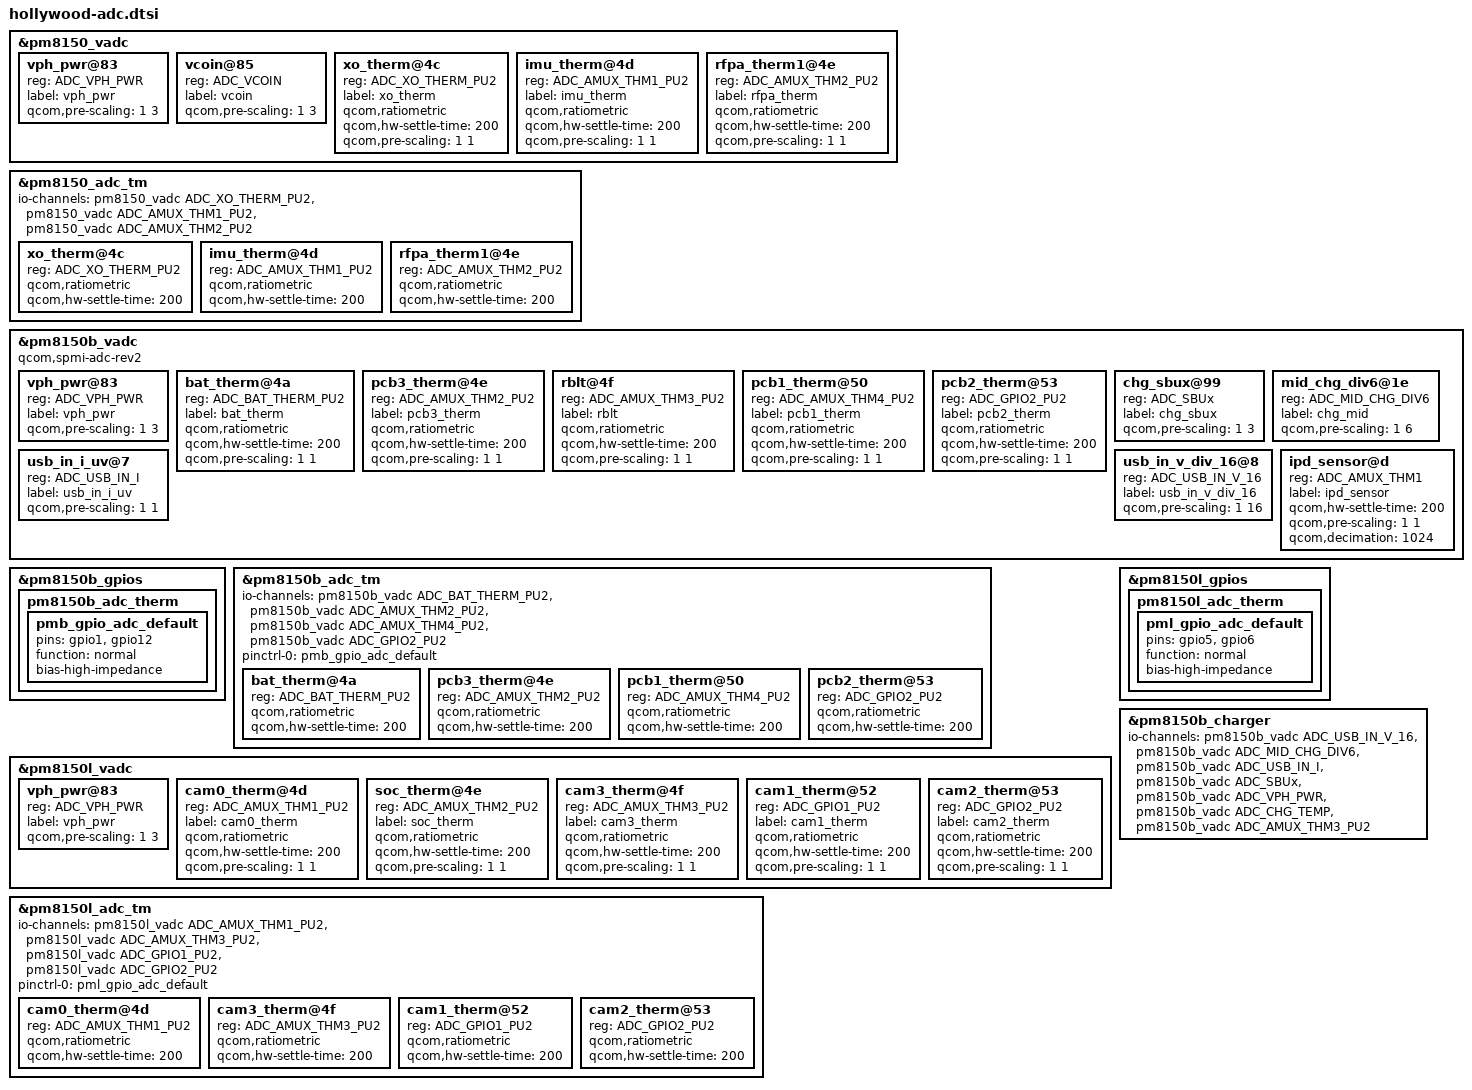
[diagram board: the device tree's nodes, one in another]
&pm8150_vadc {
	#address-cells = <1>;
	#size-cells = <0>;

	vph_pwr@83 {
		reg = <ADC_VPH_PWR>;
		label = "vph_pwr";
		qcom,pre-scaling = <1 3>;
	};

	vcoin@85 {
		reg = <ADC_VCOIN>;
		label = "vcoin";
		qcom,pre-scaling = <1 3>;
	};

	xo_therm@4c {
		reg = <ADC_XO_THERM_PU2>;
		label = "xo_therm";
		qcom,ratiometric;
		qcom,hw-settle-time = <200>;
		qcom,pre-scaling = <1 1>;
	};

	imu_therm@4d {
		reg = <ADC_AMUX_THM1_PU2>;
		label = "imu_therm";
		qcom,ratiometric;
		qcom,hw-settle-time = <200>;
		qcom,pre-scaling = <1 1>;
	};

	rfpa_therm1@4e {
		reg = <ADC_AMUX_THM2_PU2>;
		label = "rfpa_therm";
		qcom,ratiometric;
		qcom,hw-settle-time = <200>;
		qcom,pre-scaling = <1 1>;
	};
};

&pm8150_adc_tm {
	#address-cells = <1>;
	#size-cells = <0>;

	io-channels = <&pm8150_vadc ADC_XO_THERM_PU2>,
			<&pm8150_vadc ADC_AMUX_THM1_PU2>,
			<&pm8150_vadc ADC_AMUX_THM2_PU2>;

	xo_therm@4c {
		reg = <ADC_XO_THERM_PU2>;
		qcom,ratiometric;
		qcom,hw-settle-time = <200>;
	};

	imu_therm@4d {
		reg = <ADC_AMUX_THM1_PU2>;
		qcom,ratiometric;
		qcom,hw-settle-time = <200>;
	};

	rfpa_therm1@4e {
		reg = <ADC_AMUX_THM2_PU2>;
		qcom,ratiometric;
		qcom,hw-settle-time = <200>;
	};
};

&pm8150b_vadc {
	#address-cells = <1>;
	#size-cells = <0>;
	compatible = "qcom,spmi-adc-rev2";
	vph_pwr@83 {
		reg = <ADC_VPH_PWR>;
		label = "vph_pwr";
		qcom,pre-scaling = <1 3>;
	};

	bat_therm@4a {
		reg = <ADC_BAT_THERM_PU2>;
		label = "bat_therm";
		qcom,ratiometric;
		qcom,hw-settle-time = <200>;
		qcom,pre-scaling = <1 1>;
	};

	pcb3_therm@4e {
		reg = <ADC_AMUX_THM2_PU2>;
		label = "pcb3_therm";
		qcom,ratiometric;
		qcom,hw-settle-time = <200>;
		qcom,pre-scaling = <1 1>;
	};

	rblt@4f {
		reg = <ADC_AMUX_THM3_PU2>;
		label = "rblt";
		qcom,ratiometric;
		qcom,hw-settle-time = <200>;
		qcom,pre-scaling = <1 1>;
	};

	pcb1_therm@50 {
		reg = <ADC_AMUX_THM4_PU2>;
		label = "pcb1_therm";
		qcom,ratiometric;
		qcom,hw-settle-time = <200>;
		qcom,pre-scaling = <1 1>;
	};

	pcb2_therm@53 {
		reg = <ADC_GPIO2_PU2>;
		label = "pcb2_therm";
		qcom,ratiometric;
		qcom,hw-settle-time = <200>;
		qcom,pre-scaling = <1 1>;
	};

	chg_sbux@99 {
		reg = <ADC_SBUx>;
		label = "chg_sbux";
		qcom,pre-scaling = <1 3>;
	};

	mid_chg_div6@1e {
		reg = <ADC_MID_CHG_DIV6>;
		label = "chg_mid";
		qcom,pre-scaling = <1 6>;
	};

	usb_in_i_uv@7 {
		reg = <ADC_USB_IN_I>;
		label = "usb_in_i_uv";
		qcom,pre-scaling = <1 1>;
	};

	usb_in_v_div_16@8 {
		reg = <ADC_USB_IN_V_16>;
		label = "usb_in_v_div_16";
		qcom,pre-scaling = <1 16>;
	};

	ipd_sensor@d{
		reg = <ADC_AMUX_THM1>;
		label = "ipd_sensor";
		qcom,hw-settle-time = <200>;
		qcom,pre-scaling = <1 1>;
		qcom,decimation = <1024>;
	};
};

&pm8150b_gpios {
	pm8150b_adc_therm {
		pmb_gpio_adc_default: pmb_gpio_adc_default {
			pins = "gpio1", "gpio12";
			function = "normal";
			bias-high-impedance;
		};
	};
};

&pm8150b_adc_tm {
	#address-cells = <1>;
	#size-cells = <0>;

	io-channels = <&pm8150b_vadc ADC_BAT_THERM_PU2>,
			<&pm8150b_vadc ADC_AMUX_THM2_PU2>,
			<&pm8150b_vadc ADC_AMUX_THM4_PU2>,
			<&pm8150b_vadc ADC_GPIO2_PU2>;

	pinctrl-names = "default";
	pinctrl-0 = <&pmb_gpio_adc_default>;

	bat_therm@4a {
		reg = <ADC_BAT_THERM_PU2>;
		qcom,ratiometric;
		qcom,hw-settle-time = <200>;
	};

	pcb3_therm@4e {
		reg = <ADC_AMUX_THM2_PU2>;
		qcom,ratiometric;
		qcom,hw-settle-time = <200>;
	};

	pcb1_therm@50 {
		reg = <ADC_AMUX_THM4_PU2>;
		qcom,ratiometric;
		qcom,hw-settle-time = <200>;
	};

	pcb2_therm@53 {
		reg = <ADC_GPIO2_PU2>;
		qcom,ratiometric;
		qcom,hw-settle-time = <200>;
	};
};

&pm8150l_vadc {
	#address-cells = <1>;
	#size-cells = <0>;

	vph_pwr@83 {
		reg = <ADC_VPH_PWR>;
		label = "vph_pwr";
		qcom,pre-scaling = <1 3>;
	};

	cam0_therm@4d {
		reg = <ADC_AMUX_THM1_PU2>;
		label = "cam0_therm";
		qcom,ratiometric;
		qcom,hw-settle-time = <200>;
		qcom,pre-scaling = <1 1>;
	};

	soc_therm@4e {
		reg = <ADC_AMUX_THM2_PU2>;
		label = "soc_therm";
		qcom,ratiometric;
		qcom,hw-settle-time = <200>;
		qcom,pre-scaling = <1 1>;
	};

	cam3_therm@4f {
		reg = <ADC_AMUX_THM3_PU2>;
		label = "cam3_therm";
		qcom,ratiometric;
		qcom,hw-settle-time = <200>;
		qcom,pre-scaling = <1 1>;
	};

	cam1_therm@52 {
		reg = <ADC_GPIO1_PU2>;
		label = "cam1_therm";
		qcom,ratiometric;
		qcom,hw-settle-time = <200>;
		qcom,pre-scaling = <1 1>;
	};

	cam2_therm@53 {
		reg = <ADC_GPIO2_PU2>;
		label = "cam2_therm";
		qcom,ratiometric;
		qcom,hw-settle-time = <200>;
		qcom,pre-scaling = <1 1>;
	};
};

&pm8150l_gpios {
	pm8150l_adc_therm {
		pml_gpio_adc_default: pml_gpio_adc_default {
			pins = "gpio5", "gpio6";
			function = "normal";
			bias-high-impedance;
		};
	};
};

&pm8150l_adc_tm {
	#address-cells = <1>;
	#size-cells = <0>;

	io-channels = <&pm8150l_vadc ADC_AMUX_THM1_PU2>,
			<&pm8150l_vadc ADC_AMUX_THM3_PU2>,
			<&pm8150l_vadc ADC_GPIO1_PU2>,
			<&pm8150l_vadc ADC_GPIO2_PU2>;

	pinctrl-names = "default";
	pinctrl-0 = <&pml_gpio_adc_default>;

	cam0_therm@4d {
		reg = <ADC_AMUX_THM1_PU2>;
		qcom,ratiometric;
		qcom,hw-settle-time = <200>;
	};

	cam3_therm@4f {
		reg = <ADC_AMUX_THM3_PU2>;
		qcom,ratiometric;
		qcom,hw-settle-time = <200>;
	};

	cam1_therm@52 {
		reg = <ADC_GPIO1_PU2>;
		qcom,ratiometric;
		qcom,hw-settle-time = <200>;
	};

	cam2_therm@53 {
		reg = <ADC_GPIO2_PU2>;
		qcom,ratiometric;
		qcom,hw-settle-time = <200>;
	};
};

&pm8150b_charger {
	io-channels = <&pm8150b_vadc ADC_USB_IN_V_16>,
		<&pm8150b_vadc ADC_MID_CHG_DIV6>,
		<&pm8150b_vadc ADC_USB_IN_I>,
		<&pm8150b_vadc ADC_SBUx>,
		<&pm8150b_vadc ADC_VPH_PWR>,
		<&pm8150b_vadc ADC_CHG_TEMP>,
		<&pm8150b_vadc ADC_AMUX_THM3_PU2>;
	io-channel-names = "usb_in_voltage",
		"mid_voltage",
		"usb_in_current",
		"sbux_res",
		"vph_voltage",
		"chg_temp",
		"rblt_res";
};
